# dm648_cslr_gpio_001 register map
Vendor: Texas Instruments
Peripheral module from a debugger description file.
Registers are 32-bit, read-write, reset 0x0 unless marked. A register's access mark holds for its fields unless they carry their own. Offsets are as the file gives them; lines under a group give offsets from that group; [hi:lo] are bit positions; {n}, {i} and the like mark numbered series; 'fields as' and 'values as' point back to an identical list; <NAME> marks a mode.

## GPIO — General Purpose Input Output
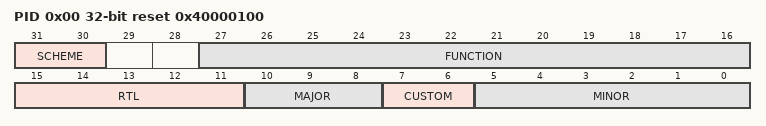
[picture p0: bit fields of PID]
0x00 PID access not given reset 0x40000100 (reset mask 0xF000FFFF) — Peripheral ID Register
  [31:30] SCHEME ro — PID encoding scheme
  [27:16] FUNCTION ro
  [15:11] RTL ro — RTL Identification
  [10:8] MAJOR ro — Major Revision
  [7:6] CUSTOM ro — Custom identification
  [5:0] MINOR ro — Minor Revision
0x08 BINTEN access not given — GPIO Interrupt Per-Bank Enable Register
  [6:0] EN_7 rw — Per-bank interrupt enable There are 7 banks of 16 GPIOs each. Bit i stands for bank i
    0=DISABLE; 1=ENABLE
0x10 DIR01 reset 0x1 — GPIO Direction Bank 0 and 1 Register
  [31:0] DIR_32 — Direction of GPIO bank 0 & 1. Bits 0-15 form bank 0 and bits 16-31 form bank 1
    0=OUT (Output); 1=IN (Input)
0x14 OUT_DATA01 — GPIO Output Data Bank 0 and 1 Register
  [31:0] OUT_32 — Output drive state of GPIO bank 0 and 1 Bits 0-15 form bank 0 and bits 16-31 form bank 1 (Ignored when configured as Input)
0x18 SET_DATA01 — GPIO Set Data 0 and 1 Register
  [31:0] SET_32 — Set output drive state of GPIO bank 0 and 1 Bits 0-15 form bank 0 and bits 16-31 form bank 1 Writing 1 sets the output drive state of corresponding GPIO. Reading it returns the output drive state
    1=SET (Set output to 1)
0x1C CLR_DATA01 — GPIO Clear Data Bank 0 and 1 Register
  [31:0] CLR_32 — Clear output drive state of GPIO bank 0 and 1 Bits 0-15 form bank 0 and bits 16-31 form bank 1 Writing 1 clears the output drive state of corresponding GPIO. Reading it returns the output drive state
    1=CLR (Clear output to 0)
0x20 IN_DATA01 ro — GPIO Input Data Bank 0 and 1 Register
  [31:0] IN_32 — Status of GPIO bank 0 and 1 Bits 0-15 form bank 0 and bits 16-31 form bank 1
    1=SET; 0=CLR
0x24 SET_RIS_TRIG01 — GPIO Set Rising Edge Interrupt Bank 0 and 1 Register
  [31:0] SETRIS_32 — Enable Rising edge interrupt detection for GPIO bank 0 and 1 Bits 0-15 form bank 0 and bits 16-31 form bank 1 Reading returns state of RIS_TRG
    1=ENABLE
0x28 CLR_RIS_TRIG01 reset 0x1 — GPIO Clear Rising Edge Interrupt Bank 0 and 1 Register
  [31:0] CLRRIS_32 — Disable Rising edge interrupt detection for GPIO bank 0 and 1 Bits 0-15 form bank 0 and bits 16-31 form bank 1 Reading returns complement state of RIS_TRG
    0=DISABLE
0x2C SET_FAL_TRIG01 — GPIO Set Falling Edge Interrupt Bank 0 and 1 Register
  [31:0] SETFAL_32 — Enable Falling edge interrupt detection for GPIO bank 0 and 1 Bits 0-15 form bank 0 and bits 16-31 form bank 1 Reading returns state of FAL_TRG
    1=ENABLE
0x30 CLR_FAL_TRIG01 reset 0x1 — GPIO Clear Falling Edge Interrupt Bank 0 and 1 Register
  [31:0] CLRFAL_32 — Disable Falling edge interrupt detection for GPIO bank 0 and bank 1 Bits 0-15 form bank 0 and bits 16-31 form bank 0+1 Reading returns complement state of FAL_TRG
    0=DISABLE
0x34 INTSTAT01 — GPIO Interrupt Status Bank 0 and 1 Register
  [31:0] STAT_32 — Status of GPIO bank 0 and 1 Bits 0-15 form bank 0 and bits 16-31 form bank 1 Reading 0: Interrupt didn't occur Reading 1: Interrupt occurred Writing 1: Clear interrupt status
